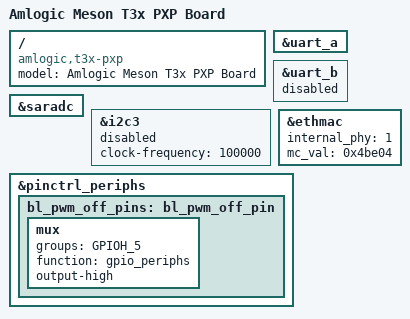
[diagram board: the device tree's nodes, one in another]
// SPDX-License-Identifier: (GPL-2.0+ OR MIT)
/*
 * Copyright (c) 2019 Amlogic, Inc. All rights reserved.
 */

/dts-v1/;

#include "meson-t3x-bc302.dtsi"
#include "meson-t3x_bc302-panel.dtsi"

/ {
	compatible = "amlogic,t3x-pxp", "amlogic,t3x-txxx", "amlogic,meson-t3x";
	model = "Amlogic Meson T3x PXP Board";
};

/* This UART is brought out to the DB9 connector */
&uart_a {
	status = "okay";
};

&uart_b {
	status = "disabled";
};

&saradc {
	status = "okay";
};

/* demo for i2c user */
&i2c3 {
	status= "disabled";
	clock-frequency = <100000>;
	/* pinctrl-names = "default";*/
	/* pinctrl-0 = <&i2c3_master_pins2>;*/
};

&ethmac {
	status = "okay";
	internal_phy = <1>;
	mc_val = <0x4be04>;
	/*mc_val = <0x1621>;*/
};

&pinctrl_periphs {
	bl_pwm_off_pins:bl_pwm_off_pin {
		mux {
			groups = "GPIOH_5";
			function = "gpio_periphs";
			output-high;
		};
	};
}; /* end of pinctrl_periphs */
